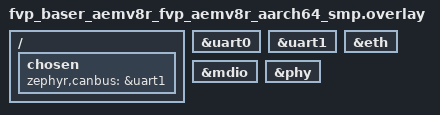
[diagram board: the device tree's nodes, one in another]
/*
 * SPDX-License-Identifier: Apache-2.0
 *
 * nros board overlay for fvp_baser_aemv8r/fvp_aemv8r_aarch64/smp.
 *
 * Zephyr's stock board DTS at
 * `boards/arm/fvp_baser_aemv8r/fvp_baser_aemv8r_fvp_aemv8r_aarch64_smp.dts`
 * already wires the GICv3, Arm arch-timer, two PL011 UARTs, the
 * 128 MiB DRAM region, and the 64 MiB flash region. The FVP's
 * SMSC91C111 ethernet model is *not* enabled by default — we patch
 * it in here so Zephyr's net stack has an L2 driver to bind to.
 *
 * Customise `local-mac-address` for runs that need a deterministic
 * GUID (e.g. Cyclone's auto-derived participant id).
 */

/ {
	chosen {
		zephyr,canbus = &uart1;
	};
};

&uart0 {
	status = "okay";
};

&uart1 {
	status = "okay";
};

/* SMSC 91C111 ethernet + its MDIO bus + PHY. The stock board DTS ships
 * these nodes disabled; enable them here so every consumer of this board
 * crate gets a working L2 interface via `nano_ros_use_board` (Cyclone DDS
 * needs one to bind its RTPS sockets — without it `dds_create_participant`
 * fails `bind to ANY:0`). Pairs with `CONFIG_ETH_SMSC91X` + `CONFIG_MDIO` +
 * `CONFIG_ETH_INIT_PRIORITY=80` in the per-board conf. phase-292 W2 / issue
 * 0232 — previously a stub that punted eth to the app; the ASI reference
 * consumer carried its own copy, but the in-tree examples had no ethernet
 * device at all. */
&eth {
	status = "okay";
};

&mdio {
	status = "okay";
};

&phy {
	status = "okay";
};
